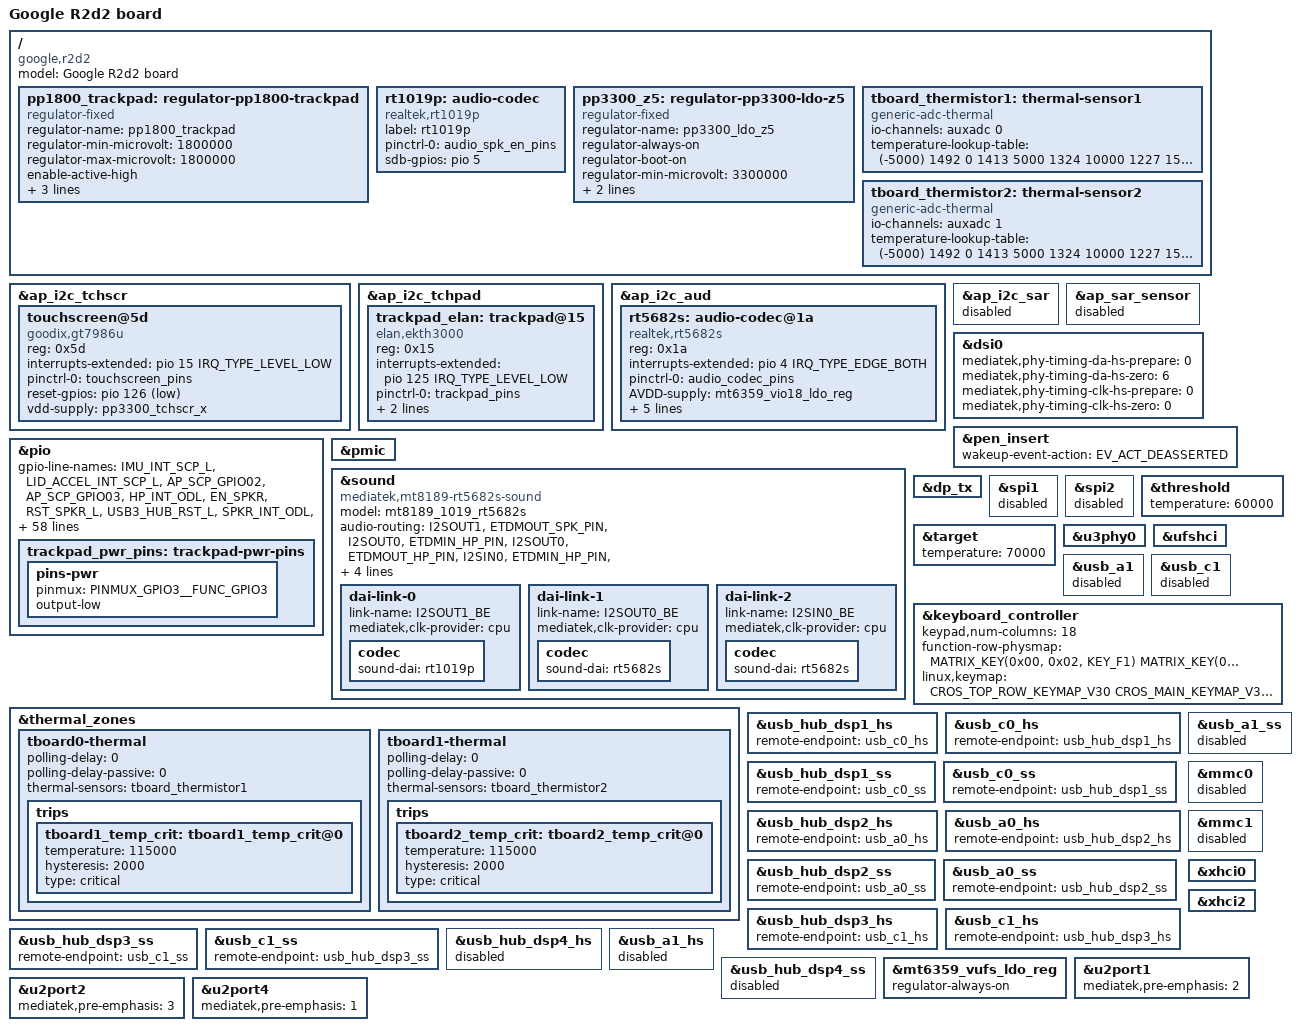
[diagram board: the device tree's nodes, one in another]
// SPDX-License-Identifier: (GPL-2.0 OR MIT)
/*
 * Copyright (C) 2025 Google Inc.
 */
/dts-v1/;
#include "mt8189-skywalker.dtsi"

/ {
	model = "Google R2d2 board";
	compatible = "google,r2d2", "mediatek,mt8189";

	pp1800_trackpad: regulator-pp1800-trackpad {
		compatible = "regulator-fixed";
		regulator-name = "pp1800_trackpad";
		regulator-min-microvolt = <1800000>;
		regulator-max-microvolt = <1800000>;
		enable-active-high;
		gpio = <&pio 3 GPIO_ACTIVE_HIGH>;
		pinctrl-names = "default";
		pinctrl-0 = <&trackpad_pwr_pins>;
		vin-supply = <&pp3300_z1>;
	};

	/delete-node/ rt9123;

	rt1019p: audio-codec {
		compatible = "realtek,rt1019p";
		label = "rt1019p";
		#sound-dai-cells = <0>;
		pinctrl-names = "default";
		pinctrl-0 = <&audio_spk_en_pins>;
		sdb-gpios = <&pio 5 GPIO_ACTIVE_HIGH>;
	};

	/* system wide LDO 3.3V power rail */
	pp3300_z5: regulator-pp3300-ldo-z5 {
		compatible = "regulator-fixed";
		regulator-name = "pp3300_ldo_z5";
		regulator-always-on;
		regulator-boot-on;
		regulator-min-microvolt = <3300000>;
		regulator-max-microvolt = <3300000>;
		vin-supply = <&ppvar_sys>;
	};

	tboard_thermistor1: thermal-sensor1 {
		compatible = "generic-adc-thermal";
		#thermal-sensor-cells = <0>;
		io-channels = <&auxadc 0>;
		io-channel-names = "sensor-channel";
		temperature-lookup-table = <    (-5000) 1492
						0 1413
						5000 1324
						10000 1227
						15000 1121
						20000 1017
						25000 900
						30000 797
						35000 698
						40000 606
						45000 522
						50000 449
						55000 383
						60000 327
						65000 278
						70000 236
						75000 201
						80000 171
						85000 145
						90000 163
						95000 124
						100000 91
						105000 78
						110000 67
						115000 58
						120000 50
						125000 44>;
	};

	tboard_thermistor2: thermal-sensor2 {
		compatible = "generic-adc-thermal";
		#thermal-sensor-cells = <0>;
		io-channels = <&auxadc 1>;
		io-channel-names = "sensor-channel";
		temperature-lookup-table = <    (-5000) 1492
						0 1413
						5000 1324
						10000 1227
						15000 1121
						20000 1017
						25000 900
						30000 797
						35000 698
						40000 606
						45000 522
						50000 449
						55000 383
						60000 327
						65000 278
						70000 236
						75000 201
						80000 171
						85000 145
						90000 163
						95000 124
						100000 91
						105000 78
						110000 67
						115000 58
						120000 50
						125000 44>;
	};
};

&ap_i2c_tchscr {
	/delete-node/ touchscreen@41;

	touchscreen@5d {
		compatible = "goodix,gt7986u", "goodix,gt7375p";
		reg = <0x5d>;
		interrupts-extended = <&pio 15 IRQ_TYPE_LEVEL_LOW>;
		pinctrl-names = "default";
		pinctrl-0 = <&touchscreen_pins>;
		reset-gpios = <&pio 126 GPIO_ACTIVE_LOW>;
		vdd-supply = <&pp3300_tchscr_x>;
		status = "okay";
	};
};

&ap_i2c_tchpad  {
	/delete-node/ trackpad@15;

	trackpad_elan: trackpad@15 {
		compatible = "elan,ekth3000";
		reg = <0x15>;
		interrupts-extended = <&pio 125 IRQ_TYPE_LEVEL_LOW>;
		pinctrl-names = "default";
		pinctrl-0 = <&trackpad_pins>;
		wakeup-source;
		vcc-supply = <&pp1800_trackpad>;
		status = "okay";
	};
};

&ap_i2c_aud {
	/delete-node/ audio-codec@1a;

	rt5682s: audio-codec@1a {
		compatible = "realtek,rt5682s";
		reg = <0x1a>;
		interrupts-extended = <&pio 4 IRQ_TYPE_EDGE_BOTH>;
		pinctrl-names = "default";
		pinctrl-0 = <&audio_codec_pins>;
		#sound-dai-cells = <0>;

		AVDD-supply = <&mt6359_vio18_ldo_reg>;
		DBVDD-supply = <&mt6359_vio18_ldo_reg>;
		LDO1-IN-supply = <&mt6359_vio18_ldo_reg>;
		MICVDD-supply = <&pp3300_z1>;
		VBAT-supply = <&pp3300_z5>;
		realtek,jd-src = <1>;
	};
};

&ap_i2c_sar {
	status = "disabled";
};

&ap_sar_sensor {
	status = "disabled";
};

&dsi0 {
	mediatek,phy-timing-da-hs-prepare = <0>;
	mediatek,phy-timing-da-hs-zero = <6>;
	mediatek,phy-timing-clk-hs-prepare = <0>;
	mediatek,phy-timing-clk-hs-zero = <0>;
};

&pen_insert {
	wakeup-event-action = <EV_ACT_DEASSERTED>;
};

&pio{
	/* 182 lines */
	gpio-line-names =
		"IMU_INT_SCP_L",		/* 0 */
		"LID_ACCEL_INT_SCP_L",
		"AP_SCP_GPIO02",
		"AP_SCP_GPIO03",
		"HP_INT_ODL",
		"EN_SPKR",
		"RST_SPKR_L",
		"USB3_HUB_RST_L",
		"SPKR_INT_ODL",
		"WWAN_INT_ODL",
		"WWAN_RESET_L",			/* 10 */
		"PEN_EJECT_OD",
		"TP",
		"EDP_BL_EN_1V8",
		"TCHSCR_REPORT_DISABLE",
		"TCHSCR_INT_1V8_ODL",
		"AP_FLASH_WP_L",
		"EC_AP_DPOC_EN_ODL",
		"",
		"",
		"",				/* 20 */
		"",
		"",
		"",
		"",
		"EN_PP3300_EDP_X",
		"",
		"EC_AP_DP_HPD_L",
		"EDP_HPD_1V8",
		"BL_PWM_1V8",
		"TP",		/* 30 */
		"UART_AP_TX_GSC_DBG_RX",
		"UART_GSC_DBG_TX_AP_RX",
		"AP_UART1_TXD",
		"AP_UART1_RXD",
		"AP_UART2_TXD",
		"AP_UART2_RXD",
		"AP_UART3_TXD",
		"AP_UART3_RXD",
		"AP_JTAG_TMS",
		"AP_JTAG_TCK",			/* 40 */
		"AP_JTAG_TDI",
		"AP_JTAG_TDO",
		"AP_JTAG_TRST_L",
		"AP_KPCOL0",
		"TP",
		"TP",
		"TP",
		"PCIE_WLAN_WAKE_OBFF_1V8_ODL",
		"PCIE_WLAN_RST_1V8_L",
		"PCIE_WLAN_CLKREQ_1V8_ODL",	/* 50 */
		"SCP_I2C_SENSOR_SCL_1V8",
		"SCP_I2C_SENSOR_SDA_1V8",
		"TP",
		"TP",
		"AP_I2C_AUD_SCL_1V8",
		"AP_I2C_AUD_SDA_1V8",
		"AP_I2C_TPM_SCL_1V8",
		"AP_I2C_TPM_SDA_1V8",
		"AP_I2C_TCHSCR_SCL_1V8",
		"AP_I2C_TCHSCR_SDA_1V8",	/* 60 */
		"AP_I2C_SAR_SCL_1V8",
		"AP_I2C_SAR_SDA_1V8",
		"AP_I2C_HDMI_SCL_1V8",
		"AP_I2C_HDMI_SDA_1V8",
		"AP_I2C_TCHPAD_SCL_1V8",
		"AP_I2C_TCHPAD_SDA_1V8",
		"AP_I2C_WWAN_SCL_1V8",
		"AP_I2C_WWAN_SDA_1V8",
		"SPI_AP_CS_EC_L",
		"SPI_AP_CLK_EC",		/* 70 */
		"SPI_AP_DO_EC_DI",
		"SPI_AP_DI_EC_DO",
		"TP",
		"TP",
		"TP",
		"TP",
		"SPI_AP_CS_TCHSCR_L",
		"SPI_AP_CLK_TCHSCR",
		"SPI_AP_DO_TCHSCR_DI",
		"SPI_AP_DI_TCHSCR_DO",		/* 80 */
		"",
		"",
		"",
		"",
		"",
		"",
		"",
		"PWRAP_SPI_CS_L",
		"PWRAP_SPI_CK",
		"PWRAP_SPI_MOSI",		/* 90 */
		"PWRAP_SPI_MISO",
		"SRCLKENA0",
		"SRCLKENA1",
		"SCP_VREQ_VAO",
		"AP_RTC_CLK32K",
		"AP_PMIC_WDTRST_L",
		"AUD_CLK_MOSI (Strap)",
		"AUD_SYNC_MOSI (Strap)",
		"AUD_DAT_MOSI0 (Strap)",
		"AUD_DAT_MOSI1 (Strap)",	/* 100 */
		"AUD_DAT_MISO0 (Strap)",
		"AUD_DAT_MISO1 (Strap)",
		"TP",
		"TP",
		"TP",
		"I2S_HP_DI",
		"I2S_HP_MCK",
		"I2S_HP_BCK",
		"I2S_HP_LRCK",
		"I2S_HP_DO",			/* 110 */
		"I2S_SPKR_MCK",
		"I2S_SPKR_BCK",
		"I2S_SPKR_LRCK",
		"I2S_SPKR_DO",
		"PCM_HDMI_CLK",
		"PCM_HDMI_SYNC",
		"TP",
		"PCM_HDMI_DO",
		"DMIC0_CLK",
		"DMIC0_DATA",			/* 120 */
		"EN_PP3300_WWAN_X",
		"DMIC1_CLK",
		"DMIC1_DATA",
		"TP",
		"TCHPAD_INT_ODL",
		"TCHSCR_RST_1V8_L",
		"AP_HDMI_RST_ODL",
		"HDMI_AP_INT_ODL",
		"TP",
		"I2S_SPKR_DI",			/* 130 */
		"AP_XHCI_INIT_DONE",
		"EC_AP_INT_ODL",
		"TP",
		"TP",
		"EN_HDMI_PWR",
		"TP",
		"AP_EC_WARM_RST_REQ",
		"GSC_AP_INT_ODL",
		"HDMI_HPD_1V8_ODL",
		"AP_SUSPEND_L ",		/* 140 */
		"EC_AP_RSVD0_ODL",
		"EC_AP_RSVD1_ODL",
		"MT6319B_INT",
		"TP",
		"BT_KILL_1V8_L",
		"WIFI_KILL_1V8_L",
		"WWAN_PWR_OFF_L",
		"WWAN_W_DISABLE_L",
		"",
		"SPI_AP_CLK_BIOS",		/* 150 */
		"SPI_AP_CS_BIOS_L",
		"SPI_AP_DO_BIOS_DI",
		"SPI_AP_DI_BIOS_DO",
		"TP",
		"TP",
		"",
		"",
		"",
		"",
		"",				/* 160 */
		"",
		"",
		"",
		"",
		"",
		"",
		"",
		"TP",
		"TP",
		"TP",			/* 170 */
		"TP",
		"TP",
		"TP",
		"",
		"",
		"",
		"",
		"",
		"",
		"SPMI_SCL",			/* 180 */
		"SPMI_SDA",
		"EMI_RESET_N";

	trackpad_pwr_pins: trackpad-pwr-pins {
		pins-pwr {
			pinmux = <PINMUX_GPIO3__FUNC_GPIO3>;
			output-low;
		};
	};
};

&pmic {
	/delete-node/ mt6359codec;
};

&sound {
	compatible = "mediatek,mt8189-rt5682s-sound";
	model = "mt8189_1019_rt5682s";
	status = "okay";

	audio-routing = "I2SOUT1", "ETDMOUT_SPK_PIN",
			"I2SOUT0", "ETDMIN_HP_PIN",
			"I2SOUT0", "ETDMOUT_HP_PIN",
			"I2SIN0", "ETDMIN_HP_PIN",
			"I2SIN0", "ETDMOUT_HP_PIN",
			"IN1P", "Headset Mic",
			"PCM 0 Playback", "ETDMOUT_HDMI_PIN",
			"AP DMIC Capture", "AP_DMIC0_PIN",
			"AP DMIC CH34 Capture", "AP_DMIC1_PIN";

	dai-link-0 {
		link-name = "I2SOUT1_BE";
		mediatek,clk-provider = "cpu";

		codec {
			sound-dai = <&rt1019p>;
		};
	};

	dai-link-1 {
		link-name = "I2SOUT0_BE";
		mediatek,clk-provider = "cpu";

		codec {
			sound-dai = <&rt5682s>;
		};
	};

	dai-link-2 {
		link-name = "I2SIN0_BE";
		mediatek,clk-provider = "cpu";

		codec {
			sound-dai = <&rt5682s>;
		};
	};
};

&dp_tx {
	/delete-property/ mediatek,phy-flip-gpios;
};

&spi1 {
	status = "disabled";
};

&spi2 {
	status = "disabled";
};

&thermal_zones {
	tboard0-thermal {
		polling-delay = <0>; /* milliseconds */
		polling-delay-passive = <0>; /* milliseconds */
		thermal-sensors = <&tboard_thermistor1>;

		trips {
			tboard1_temp_crit: tboard1_temp_crit@0 {
				temperature = <115000>;
				hysteresis = <2000>;
				type = "critical";
			};
		};
	};

	tboard1-thermal {
		polling-delay = <0>; /* milliseconds */
		polling-delay-passive = <0>; /* milliseconds */
		thermal-sensors = <&tboard_thermistor2>;

		trips {
			tboard2_temp_crit: tboard2_temp_crit@0 {
				temperature = <115000>;
				hysteresis = <2000>;
				type = "critical";
			};
		};
	};
};

&threshold {
    temperature = <60000>;
};

&target {
    temperature = <70000>;
};

&u3phy0 {
	status = "okay";
};

&ufshci {
	status = "okay";
};

&usb_a1 {
	status = "disabled";
};

&usb_c1 {
	status = "disabled";
};

&keyboard_controller {
	keypad,num-columns = <18>;

	function-row-physmap = <
		MATRIX_KEY(0x00, 0x02, KEY_F1)	/* T1 */
		MATRIX_KEY(0x03, 0x02, KEY_F2)	/* T2 */
		MATRIX_KEY(0x02, 0x02, KEY_F3)	/* T3 */
		MATRIX_KEY(0x01, 0x02, KEY_F4)	/* T4 */
		MATRIX_KEY(0x04, 0x04, KEY_F5)	/* T5 */
		MATRIX_KEY(0x02, 0x04, KEY_F6)	/* T6 */
		MATRIX_KEY(0x01, 0x04, KEY_F7)	/* T7 */
		MATRIX_KEY(0x02, 0x0b, KEY_F8)	/* T8 */
		MATRIX_KEY(0x01, 0x09, KEY_F9)	/* T9 */
		MATRIX_KEY(0x00, 0x04, KEY_F10)	/* T10 */
		MATRIX_KEY(0x00, 0x01, KEY_F11)	/* T11 */
		MATRIX_KEY(0x01, 0x05, KEY_F12)	/* T12 */
		MATRIX_KEY(0x03, 0x05, KEY_F13)	/* T13 */
		MATRIX_KEY(0x03, 0x09, KEY_F14)	/* T14 */
	>;

	linux,keymap = <
		CROS_TOP_ROW_KEYMAP_V30
		CROS_MAIN_KEYMAP_V30
		MATRIX_KEY(0x00, 0x02, KEY_BACK)
		MATRIX_KEY(0x03, 0x02, KEY_REFRESH)
		MATRIX_KEY(0x02, 0x02, KEY_ZOOM)
		MATRIX_KEY(0x01, 0x02, KEY_SCALE)
		MATRIX_KEY(0x04, 0x04, KEY_SYSRQ)
		MATRIX_KEY(0x02, 0x04, KEY_BRIGHTNESSDOWN)
		MATRIX_KEY(0x01, 0x04, KEY_BRIGHTNESSUP)
		MATRIX_KEY(0x02, 0x0b, KEY_DICTATE)
		MATRIX_KEY(0x01, 0x09, KEY_ACCESSIBILITY)
		MATRIX_KEY(0x00, 0x04, KEY_PLAYPAUSE)
		MATRIX_KEY(0x00, 0x01, KEY_MICMUTE)
		MATRIX_KEY(0x01, 0x05, KEY_MUTE)
		MATRIX_KEY(0x03, 0x05, KEY_VOLUMEDOWN)
		MATRIX_KEY(0x03, 0x09, KEY_VOLUMEUP)
	>;
};

/* USB hub port 1 */
&usb_hub_dsp1_hs {
	remote-endpoint = <&usb_c0_hs>;
};

&usb_c0_hs {
	remote-endpoint = <&usb_hub_dsp1_hs>;
};

&usb_hub_dsp1_ss {
	remote-endpoint = <&usb_c0_ss>;
};

&usb_c0_ss {
	remote-endpoint = <&usb_hub_dsp1_ss>;
};

/* USB hub port 2 */
&usb_hub_dsp2_hs {
	remote-endpoint = <&usb_a0_hs>;
};

&usb_a0_hs {
	remote-endpoint = <&usb_hub_dsp2_hs>;
};

&usb_hub_dsp2_ss {
	remote-endpoint = <&usb_a0_ss>;
};

&usb_a0_ss {
	remote-endpoint = <&usb_hub_dsp2_ss>;
};

/* USB hub port 3 */
&usb_hub_dsp3_hs {
	remote-endpoint = <&usb_c1_hs>;
};

&usb_c1_hs {
	remote-endpoint = <&usb_hub_dsp3_hs>;
};

&usb_hub_dsp3_ss {
	remote-endpoint = <&usb_c1_ss>;
};

&usb_c1_ss {
	remote-endpoint = <&usb_hub_dsp3_ss>;
};

/* USB hub port 4 */
&usb_hub_dsp4_hs {
	status = "disabled";
};

&usb_a1_hs {
	status = "disabled";
};

&usb_hub_dsp4_ss {
	status = "disabled";
};

&usb_a1_ss {
	status = "disabled";
};

&mmc0 {
	status = "disabled";
};

&mmc1 {
	status = "disabled";
};

&mt6359_vufs_ldo_reg {
	regulator-always-on;
};

&xhci0 {
	status = "okay";
};

&xhci2 {
	status = "okay";
};

// Add WCAM, UCAM, Bluetooth
&u2port1{
	mediatek,pre-emphasis = <2>;
};

&u2port2{
	mediatek,pre-emphasis = <3>;
};

&u2port4{
	mediatek,pre-emphasis = <1>;
};
